VERSION "0.0"

NS_ :

BS_:

BU_: HUB REARSTEER DIFF_F FUEL SENSORV2 POWERTRAIN GPS DIFF_R

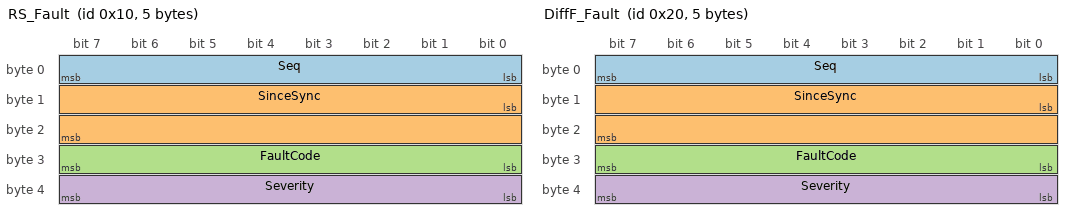
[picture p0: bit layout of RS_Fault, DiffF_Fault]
BO_ 16 RS_Fault: 5 REARSTEER
 SG_ Seq : 0|8@1+ (1,0) [0|255] "" HUB
 SG_ SinceSync : 8|16@1+ (1,0) [0|65534] "us" HUB
 SG_ FaultCode : 24|8@1+ (1,0) [0|254] "" HUB
 SG_ Severity : 32|8@1+ (1,0) [0|254] "" HUB

BO_ 32 DiffF_Fault: 5 DIFF_F
 SG_ Seq : 0|8@1+ (1,0) [0|255] "" HUB
 SG_ SinceSync : 8|16@1+ (1,0) [0|65534] "us" HUB
 SG_ FaultCode : 24|8@1+ (1,0) [0|254] "" HUB
 SG_ Severity : 32|8@1+ (1,0) [0|254] "" HUB

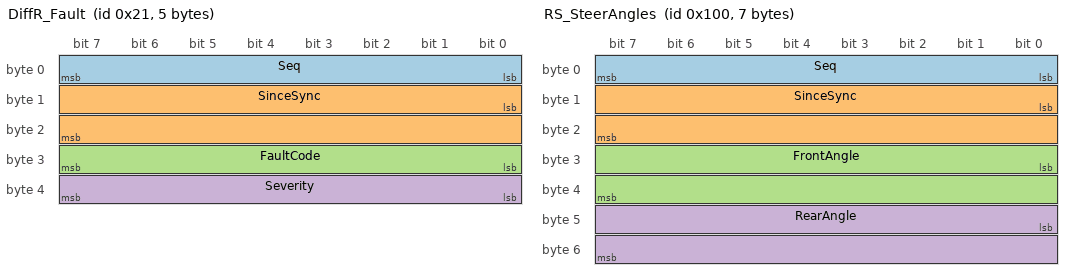
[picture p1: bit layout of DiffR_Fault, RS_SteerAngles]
BO_ 33 DiffR_Fault: 5 DIFF_R
 SG_ Seq : 0|8@1+ (1,0) [0|255] "" HUB
 SG_ SinceSync : 8|16@1+ (1,0) [0|65534] "us" HUB
 SG_ FaultCode : 24|8@1+ (1,0) [0|254] "" HUB
 SG_ Severity : 32|8@1+ (1,0) [0|254] "" HUB

BO_ 128 SYNC: 1 HUB
 SG_ SyncCounter : 0|8@1+ (1,0) [0|255] "" REARSTEER,DIFF_F,FUEL,SENSORV2,POWERTRAIN,GPS,DIFF_R

BO_ 144 GPS_Time: 4 GPS
 SG_ UtcTimeOfDay : 0|32@1+ (1,0) [0|4294967294] "ms" HUB

BO_ 256 RS_SteerAngles: 7 REARSTEER
 SG_ Seq : 0|8@1+ (1,0) [0|255] "" HUB
 SG_ SinceSync : 8|16@1+ (1,0) [0|65534] "us" HUB
 SG_ FrontAngle : 24|16@1- (0.01,0) [-327.68|327.66] "deg" HUB
 SG_ RearAngle : 40|16@1- (0.01,0) [-327.68|327.66] "deg" HUB

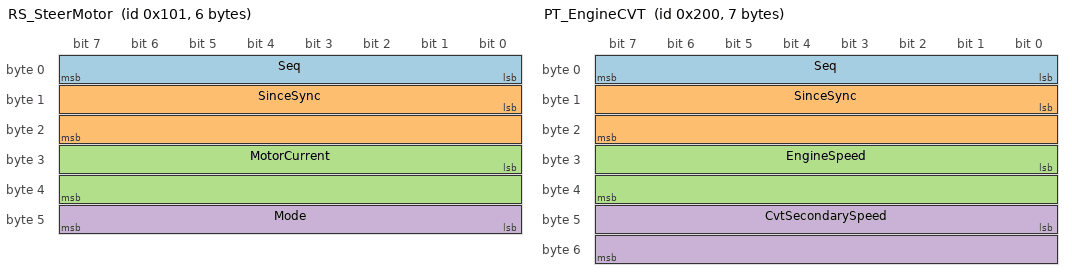
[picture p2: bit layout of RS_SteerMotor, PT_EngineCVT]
BO_ 257 RS_SteerMotor: 6 REARSTEER
 SG_ Seq : 0|8@1+ (1,0) [0|255] "" HUB
 SG_ SinceSync : 8|16@1+ (1,0) [0|65534] "us" HUB
 SG_ MotorCurrent : 24|16@1- (0.01,0) [-327.68|327.66] "A" HUB
 SG_ Mode : 40|8@1+ (1,0) [0|254] "" HUB

BO_ 512 PT_EngineCVT: 7 POWERTRAIN
 SG_ Seq : 0|8@1+ (1,0) [0|255] "" HUB
 SG_ SinceSync : 8|16@1+ (1,0) [0|65534] "us" HUB
 SG_ EngineSpeed : 24|16@1+ (1,0) [0|65534] "rpm" HUB
 SG_ CvtSecondarySpeed : 40|16@1+ (1,0) [0|65534] "rpm" HUB

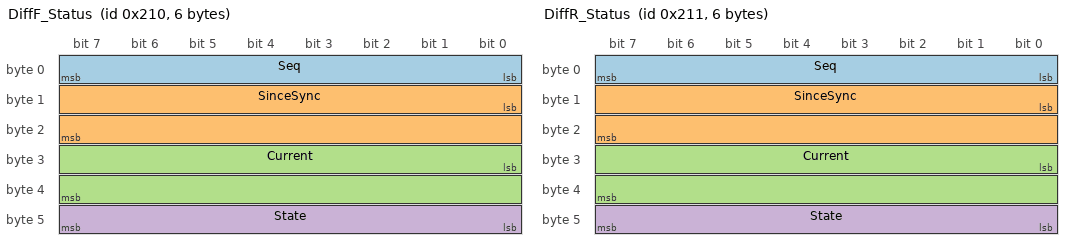
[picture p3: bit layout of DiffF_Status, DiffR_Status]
BO_ 528 DiffF_Status: 6 DIFF_F
 SG_ Seq : 0|8@1+ (1,0) [0|255] "" HUB
 SG_ SinceSync : 8|16@1+ (1,0) [0|65534] "us" HUB
 SG_ Current : 24|16@1- (0.01,0) [-327.68|327.66] "A" HUB
 SG_ State : 40|8@1+ (1,0) [0|254] "" HUB

BO_ 529 DiffR_Status: 6 DIFF_R
 SG_ Seq : 0|8@1+ (1,0) [0|255] "" HUB
 SG_ SinceSync : 8|16@1+ (1,0) [0|65534] "us" HUB
 SG_ Current : 24|16@1- (0.01,0) [-327.68|327.66] "A" HUB
 SG_ State : 40|8@1+ (1,0) [0|254] "" HUB

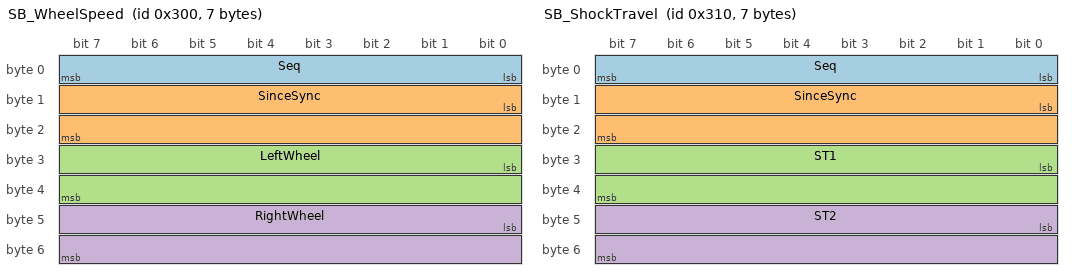
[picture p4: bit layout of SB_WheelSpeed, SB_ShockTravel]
BO_ 768 SB_WheelSpeed: 7 SENSORV2
 SG_ Seq : 0|8@1+ (1,0) [0|255] "" HUB
 SG_ SinceSync : 8|16@1+ (1,0) [0|65534] "us" HUB
 SG_ LeftWheel : 24|16@1+ (0.1,0) [0|6553.4] "rpm" HUB
 SG_ RightWheel : 40|16@1+ (0.1,0) [0|6553.4] "rpm" HUB

BO_ 784 SB_ShockTravel: 7 SENSORV2
 SG_ Seq : 0|8@1+ (1,0) [0|255] "" HUB
 SG_ SinceSync : 8|16@1+ (1,0) [0|65534] "us" HUB
 SG_ ST1 : 24|16@1+ (0.01,0) [0|655.34] "mm" HUB
 SG_ ST2 : 40|16@1+ (0.01,0) [0|655.34] "mm" HUB

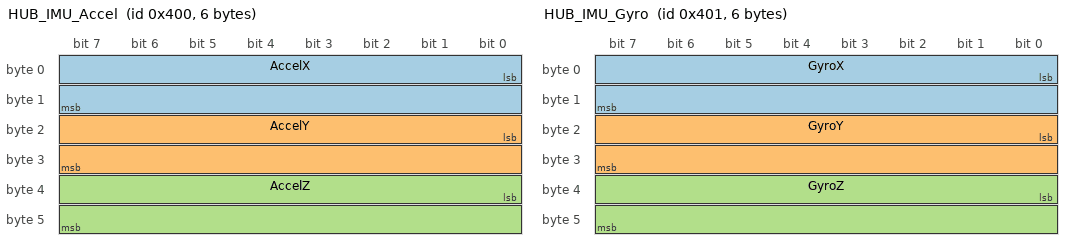
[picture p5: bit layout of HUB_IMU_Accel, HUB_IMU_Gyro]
BO_ 1024 HUB_IMU_Accel: 6 HUB
 SG_ AccelX : 0|16@1- (0.001,0) [-32.768|32.766] "g" Vector__XXX
 SG_ AccelY : 16|16@1- (0.001,0) [-32.768|32.766] "g" Vector__XXX
 SG_ AccelZ : 32|16@1- (0.001,0) [-32.768|32.766] "g" Vector__XXX

BO_ 1025 HUB_IMU_Gyro: 6 HUB
 SG_ GyroX : 0|16@1- (0.1,0) [-3276.8|3276.6] "deg/s" Vector__XXX
 SG_ GyroY : 16|16@1- (0.1,0) [-3276.8|3276.6] "deg/s" Vector__XXX
 SG_ GyroZ : 32|16@1- (0.1,0) [-3276.8|3276.6] "deg/s" Vector__XXX

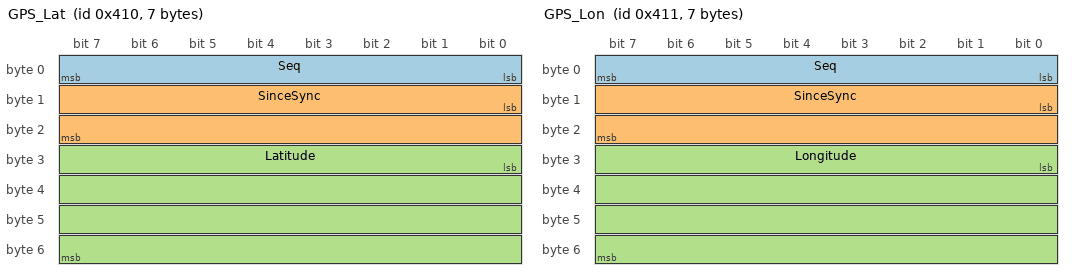
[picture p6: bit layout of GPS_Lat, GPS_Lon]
BO_ 1040 GPS_Lat: 7 GPS
 SG_ Seq : 0|8@1+ (1,0) [0|255] "" HUB
 SG_ SinceSync : 8|16@1+ (1,0) [0|65534] "us" HUB
 SG_ Latitude : 24|32@1- (1e-07,0) [-214.7483648|214.7483646] "deg" HUB

BO_ 1041 GPS_Lon: 7 GPS
 SG_ Seq : 0|8@1+ (1,0) [0|255] "" HUB
 SG_ SinceSync : 8|16@1+ (1,0) [0|65534] "us" HUB
 SG_ Longitude : 24|32@1- (1e-07,0) [-214.7483648|214.7483646] "deg" HUB

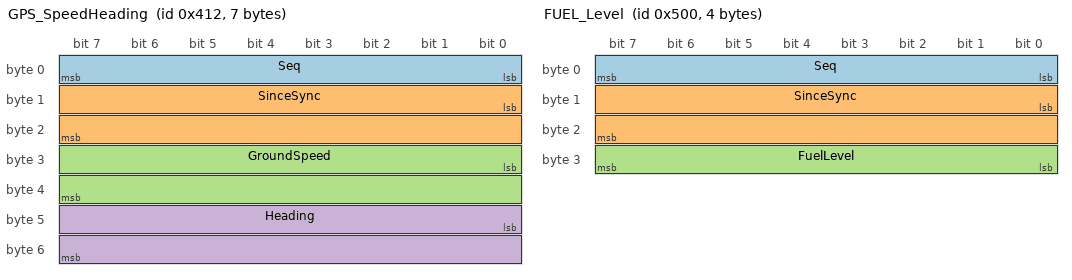
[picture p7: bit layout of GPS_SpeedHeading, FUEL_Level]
BO_ 1042 GPS_SpeedHeading: 7 GPS
 SG_ Seq : 0|8@1+ (1,0) [0|255] "" HUB
 SG_ SinceSync : 8|16@1+ (1,0) [0|65534] "us" HUB
 SG_ GroundSpeed : 24|16@1+ (0.01,0) [0|655.34] "m/s" HUB
 SG_ Heading : 40|16@1+ (0.01,0) [0|655.34] "deg" HUB

BO_ 1280 FUEL_Level: 4 FUEL
 SG_ Seq : 0|8@1+ (1,0) [0|255] "" HUB
 SG_ SinceSync : 8|16@1+ (1,0) [0|65534] "us" HUB
 SG_ FuelLevel : 24|8@1+ (0.5,0) [0|127] "%" HUB

BO_ 1296 HUB_Battery: 2 HUB
 SG_ BatteryVoltage : 0|16@1+ (0.01,0) [0|655.34] "V" Vector__XXX

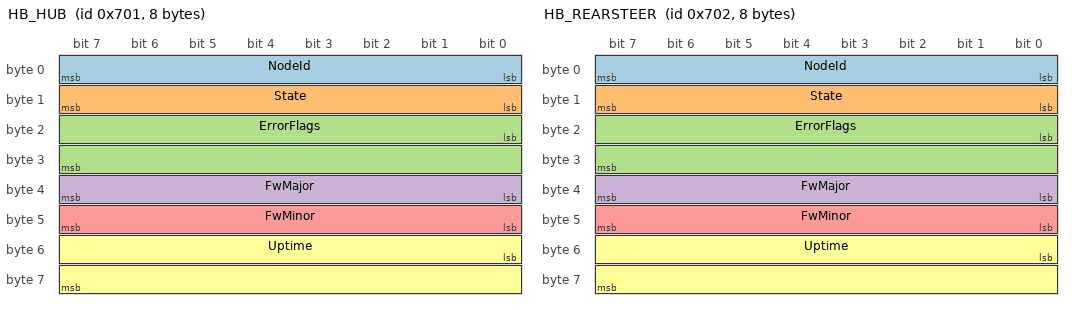
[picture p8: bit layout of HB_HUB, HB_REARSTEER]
BO_ 1793 HB_HUB: 8 HUB
 SG_ NodeId : 0|8@1+ (1,0) [0|255] "" Vector__XXX
 SG_ State : 8|8@1+ (1,0) [0|254] "" Vector__XXX
 SG_ ErrorFlags : 16|16@1+ (1,0) [0|65534] "" Vector__XXX
 SG_ FwMajor : 32|8@1+ (1,0) [0|254] "" Vector__XXX
 SG_ FwMinor : 40|8@1+ (1,0) [0|254] "" Vector__XXX
 SG_ Uptime : 48|16@1+ (1,0) [0|65534] "s" Vector__XXX

BO_ 1794 HB_REARSTEER: 8 REARSTEER
 SG_ NodeId : 0|8@1+ (1,0) [0|255] "" HUB
 SG_ State : 8|8@1+ (1,0) [0|254] "" HUB
 SG_ ErrorFlags : 16|16@1+ (1,0) [0|65534] "" HUB
 SG_ FwMajor : 32|8@1+ (1,0) [0|254] "" HUB
 SG_ FwMinor : 40|8@1+ (1,0) [0|254] "" HUB
 SG_ Uptime : 48|16@1+ (1,0) [0|65534] "s" HUB

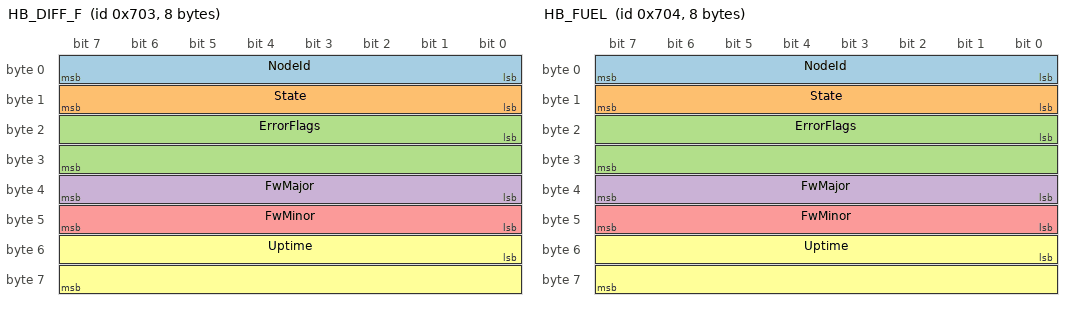
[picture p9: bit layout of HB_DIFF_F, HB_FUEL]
BO_ 1795 HB_DIFF_F: 8 DIFF_F
 SG_ NodeId : 0|8@1+ (1,0) [0|255] "" HUB
 SG_ State : 8|8@1+ (1,0) [0|254] "" HUB
 SG_ ErrorFlags : 16|16@1+ (1,0) [0|65534] "" HUB
 SG_ FwMajor : 32|8@1+ (1,0) [0|254] "" HUB
 SG_ FwMinor : 40|8@1+ (1,0) [0|254] "" HUB
 SG_ Uptime : 48|16@1+ (1,0) [0|65534] "s" HUB

BO_ 1796 HB_FUEL: 8 FUEL
 SG_ NodeId : 0|8@1+ (1,0) [0|255] "" HUB
 SG_ State : 8|8@1+ (1,0) [0|254] "" HUB
 SG_ ErrorFlags : 16|16@1+ (1,0) [0|65534] "" HUB
 SG_ FwMajor : 32|8@1+ (1,0) [0|254] "" HUB
 SG_ FwMinor : 40|8@1+ (1,0) [0|254] "" HUB
 SG_ Uptime : 48|16@1+ (1,0) [0|65534] "s" HUB

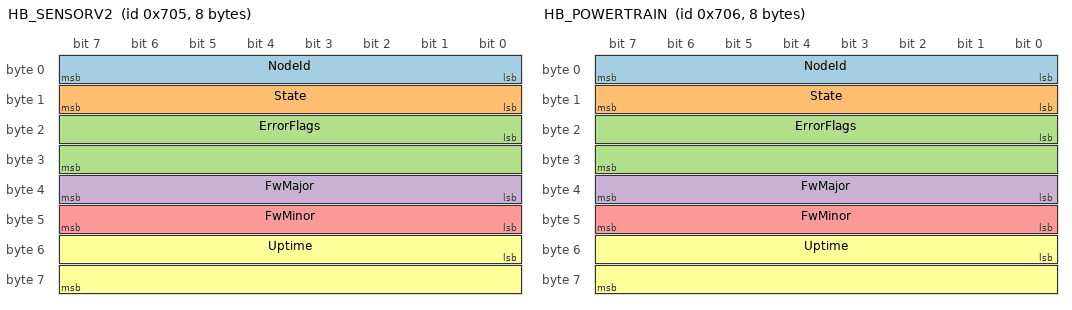
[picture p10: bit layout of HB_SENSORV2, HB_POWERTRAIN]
BO_ 1797 HB_SENSORV2: 8 SENSORV2
 SG_ NodeId : 0|8@1+ (1,0) [0|255] "" HUB
 SG_ State : 8|8@1+ (1,0) [0|254] "" HUB
 SG_ ErrorFlags : 16|16@1+ (1,0) [0|65534] "" HUB
 SG_ FwMajor : 32|8@1+ (1,0) [0|254] "" HUB
 SG_ FwMinor : 40|8@1+ (1,0) [0|254] "" HUB
 SG_ Uptime : 48|16@1+ (1,0) [0|65534] "s" HUB

BO_ 1798 HB_POWERTRAIN: 8 POWERTRAIN
 SG_ NodeId : 0|8@1+ (1,0) [0|255] "" HUB
 SG_ State : 8|8@1+ (1,0) [0|254] "" HUB
 SG_ ErrorFlags : 16|16@1+ (1,0) [0|65534] "" HUB
 SG_ FwMajor : 32|8@1+ (1,0) [0|254] "" HUB
 SG_ FwMinor : 40|8@1+ (1,0) [0|254] "" HUB
 SG_ Uptime : 48|16@1+ (1,0) [0|65534] "s" HUB

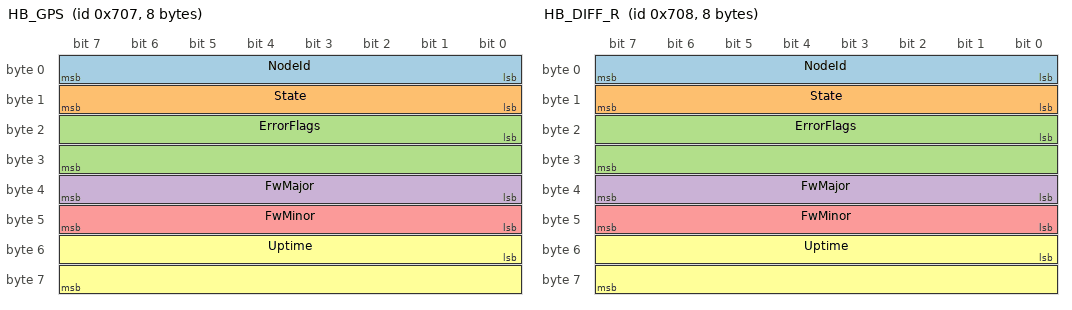
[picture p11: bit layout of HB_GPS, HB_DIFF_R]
BO_ 1799 HB_GPS: 8 GPS
 SG_ NodeId : 0|8@1+ (1,0) [0|255] "" HUB
 SG_ State : 8|8@1+ (1,0) [0|254] "" HUB
 SG_ ErrorFlags : 16|16@1+ (1,0) [0|65534] "" HUB
 SG_ FwMajor : 32|8@1+ (1,0) [0|254] "" HUB
 SG_ FwMinor : 40|8@1+ (1,0) [0|254] "" HUB
 SG_ Uptime : 48|16@1+ (1,0) [0|65534] "s" HUB

BO_ 1800 HB_DIFF_R: 8 DIFF_R
 SG_ NodeId : 0|8@1+ (1,0) [0|255] "" HUB
 SG_ State : 8|8@1+ (1,0) [0|254] "" HUB
 SG_ ErrorFlags : 16|16@1+ (1,0) [0|65534] "" HUB
 SG_ FwMajor : 32|8@1+ (1,0) [0|254] "" HUB
 SG_ FwMinor : 40|8@1+ (1,0) [0|254] "" HUB
 SG_ Uptime : 48|16@1+ (1,0) [0|65534] "s" HUB

CM_ "Baja DAQ CAN spec v0 (frozen Oct 19 2026). CAN 2.0A, 1 Mbit/s, little-endian. All-ones raw value (0xFF, 0xFFFF, 0x7FFF signed) = not available. Owner: Toph Jones.";
CM_ SG_ 16 Seq "Sequence counter, +1 per message on this ID, wraps 255->0";
CM_ SG_ 16 SinceSync "us since last SYNC (0x080); 0xFFFF = no SYNC yet";
CM_ BO_ 16 "Sent on change, then 10 Hz while active";
CM_ SG_ 32 Seq "Sequence counter, +1 per message on this ID, wraps 255->0";
CM_ SG_ 32 SinceSync "us since last SYNC (0x080); 0xFFFF = no SYNC yet";
CM_ SG_ 32 FaultCode "Codes defined by diff team";
CM_ BO_ 32 "Sent on change, then 10 Hz while active";
CM_ SG_ 33 Seq "Sequence counter, +1 per message on this ID, wraps 255->0";
CM_ SG_ 33 SinceSync "us since last SYNC (0x080); 0xFFFF = no SYNC yet";
CM_ SG_ 33 FaultCode "Codes defined by diff team";
CM_ BO_ 33 "Sent on change, then 10 Hz while active";
CM_ BO_ 128 "No header. Nodes reset their us counter on receipt";
CM_ BO_ 144 "No header. Sent on PPS";
CM_ SG_ 256 Seq "Sequence counter, +1 per message on this ID, wraps 255->0";
CM_ SG_ 256 SinceSync "us since last SYNC (0x080); 0xFFFF = no SYNC yet";
CM_ SG_ 257 Seq "Sequence counter, +1 per message on this ID, wraps 255->0";
CM_ SG_ 257 SinceSync "us since last SYNC (0x080); 0xFFFF = no SYNC yet";
CM_ SG_ 512 Seq "Sequence counter, +1 per message on this ID, wraps 255->0";
CM_ SG_ 512 SinceSync "us since last SYNC (0x080); 0xFFFF = no SYNC yet";
CM_ SG_ 528 Seq "Sequence counter, +1 per message on this ID, wraps 255->0";
CM_ SG_ 528 SinceSync "us since last SYNC (0x080); 0xFFFF = no SYNC yet";
CM_ SG_ 528 State "Values defined by diff team";
CM_ SG_ 529 Seq "Sequence counter, +1 per message on this ID, wraps 255->0";
CM_ SG_ 529 SinceSync "us since last SYNC (0x080); 0xFFFF = no SYNC yet";
CM_ SG_ 529 State "Values defined by diff team";
CM_ SG_ 768 Seq "Sequence counter, +1 per message on this ID, wraps 255->0";
CM_ SG_ 768 SinceSync "us since last SYNC (0x080); 0xFFFF = no SYNC yet";
CM_ SG_ 784 Seq "Sequence counter, +1 per message on this ID, wraps 255->0";
CM_ SG_ 784 SinceSync "us since last SYNC (0x080); 0xFFFF = no SYNC yet";
CM_ BO_ 784 "Assumes ST1/ST2 are shock travel; confirm with shock team";
CM_ BO_ 1024 "Hub-internal: logged with this ID, never transmitted. No header";
CM_ BO_ 1025 "Hub-internal: logged with this ID, never transmitted. No header";
CM_ SG_ 1040 Seq "Sequence counter, +1 per message on this ID, wraps 255->0";
CM_ SG_ 1040 SinceSync "us since last SYNC (0x080); 0xFFFF = no SYNC yet";
CM_ SG_ 1041 Seq "Sequence counter, +1 per message on this ID, wraps 255->0";
CM_ SG_ 1041 SinceSync "us since last SYNC (0x080); 0xFFFF = no SYNC yet";
CM_ SG_ 1042 Seq "Sequence counter, +1 per message on this ID, wraps 255->0";
CM_ SG_ 1042 SinceSync "us since last SYNC (0x080); 0xFFFF = no SYNC yet";
CM_ SG_ 1280 Seq "Sequence counter, +1 per message on this ID, wraps 255->0";
CM_ SG_ 1280 SinceSync "us since last SYNC (0x080); 0xFFFF = no SYNC yet";
CM_ BO_ 1296 "Hub-internal: logged with this ID, never transmitted. No header";
CM_ SG_ 1793 ErrorFlags "Bits 0-7 node library: 0 no SYNC seen, 1 CAN error-passive since last HB, 2 TX queue overflow, 3 brownout/watchdog reset. Bits 8-15 node-specific";
CM_ SG_ 1793 Uptime "Seconds since power-up, wraps";
CM_ BO_ 1793 "Heartbeat, DAQ hub. No header";
CM_ SG_ 1794 ErrorFlags "Bits 0-7 node library: 0 no SYNC seen, 1 CAN error-passive since last HB, 2 TX queue overflow, 3 brownout/watchdog reset. Bits 8-15 node-specific";
CM_ SG_ 1794 Uptime "Seconds since power-up, wraps";
CM_ BO_ 1794 "Heartbeat, Rear-steer controller. No header";
CM_ SG_ 1795 ErrorFlags "Bits 0-7 node library: 0 no SYNC seen, 1 CAN error-passive since last HB, 2 TX queue overflow, 3 brownout/watchdog reset. Bits 8-15 node-specific";
CM_ SG_ 1795 Uptime "Seconds since power-up, wraps";
CM_ BO_ 1795 "Heartbeat, Front diff controller. No header";
CM_ SG_ 1796 ErrorFlags "Bits 0-7 node library: 0 no SYNC seen, 1 CAN error-passive since last HB, 2 TX queue overflow, 3 brownout/watchdog reset. Bits 8-15 node-specific";
CM_ SG_ 1796 Uptime "Seconds since power-up, wraps";
CM_ BO_ 1796 "Heartbeat, Fuel gauge (PIC). No header";
CM_ SG_ 1797 ErrorFlags "Bits 0-7 node library: 0 no SYNC seen, 1 CAN error-passive since last HB, 2 TX queue overflow, 3 brownout/watchdog reset. Bits 8-15 node-specific";
CM_ SG_ 1797 Uptime "Seconds since power-up, wraps";
CM_ BO_ 1797 "Heartbeat, SensorBoardV2: wheel speed, shock travel. No header";
CM_ SG_ 1798 ErrorFlags "Bits 0-7 node library: 0 no SYNC seen, 1 CAN error-passive since last HB, 2 TX queue overflow, 3 brownout/watchdog reset. Bits 8-15 node-specific";
CM_ SG_ 1798 Uptime "Seconds since power-up, wraps";
CM_ BO_ 1798 "Heartbeat, Engine and CVT speed node (unplanned, ID reserved). No header";
CM_ SG_ 1799 ErrorFlags "Bits 0-7 node library: 0 no SYNC seen, 1 CAN error-passive since last HB, 2 TX queue overflow, 3 brownout/watchdog reset. Bits 8-15 node-specific";
CM_ SG_ 1799 Uptime "Seconds since power-up, wraps";
CM_ BO_ 1799 "Heartbeat, GPS node (DAQ, if built). No header";
CM_ SG_ 1800 ErrorFlags "Bits 0-7 node library: 0 no SYNC seen, 1 CAN error-passive since last HB, 2 TX queue overflow, 3 brownout/watchdog reset. Bits 8-15 node-specific";
CM_ SG_ 1800 Uptime "Seconds since power-up, wraps";
CM_ BO_ 1800 "Heartbeat, Rear diff controller. No header";
CM_ BU_ HUB "Node ID 0x01: DAQ hub";
CM_ BU_ REARSTEER "Node ID 0x02: Rear-steer controller";
CM_ BU_ DIFF_F "Node ID 0x03: Front diff controller";
CM_ BU_ FUEL "Node ID 0x04: Fuel gauge (PIC)";
CM_ BU_ SENSORV2 "Node ID 0x05: SensorBoardV2: wheel speed, shock travel";
CM_ BU_ POWERTRAIN "Node ID 0x06: Engine and CVT speed node (unplanned, ID reserved)";
CM_ BU_ GPS "Node ID 0x07: GPS node (DAQ, if built)";
CM_ BU_ DIFF_R "Node ID 0x08: Rear diff controller";

BA_DEF_ BO_ "GenMsgCycleTime" INT 0 65535;
BA_DEF_ BO_ "HubInternal" INT 0 1;
BA_DEF_DEF_ "GenMsgCycleTime" 0;
BA_DEF_DEF_ "HubInternal" 0;
BA_ "GenMsgCycleTime" BO_ 128 50;
BA_ "GenMsgCycleTime" BO_ 144 1000;
BA_ "GenMsgCycleTime" BO_ 256 10;
BA_ "GenMsgCycleTime" BO_ 257 10;
BA_ "GenMsgCycleTime" BO_ 512 10;
BA_ "GenMsgCycleTime" BO_ 528 20;
BA_ "GenMsgCycleTime" BO_ 529 20;
BA_ "GenMsgCycleTime" BO_ 768 10;
BA_ "GenMsgCycleTime" BO_ 784 2;
BA_ "GenMsgCycleTime" BO_ 1024 2;
BA_ "HubInternal" BO_ 1024 1;
BA_ "GenMsgCycleTime" BO_ 1025 2;
BA_ "HubInternal" BO_ 1025 1;
BA_ "GenMsgCycleTime" BO_ 1040 100;
BA_ "GenMsgCycleTime" BO_ 1041 100;
BA_ "GenMsgCycleTime" BO_ 1042 100;
BA_ "GenMsgCycleTime" BO_ 1280 1000;
BA_ "GenMsgCycleTime" BO_ 1296 100;
BA_ "HubInternal" BO_ 1296 1;
BA_ "GenMsgCycleTime" BO_ 1793 1000;
BA_ "GenMsgCycleTime" BO_ 1794 1000;
BA_ "GenMsgCycleTime" BO_ 1795 1000;
BA_ "GenMsgCycleTime" BO_ 1796 1000;
BA_ "GenMsgCycleTime" BO_ 1797 1000;
BA_ "GenMsgCycleTime" BO_ 1798 1000;
BA_ "GenMsgCycleTime" BO_ 1799 1000;
BA_ "GenMsgCycleTime" BO_ 1800 1000;

VAL_ 16 FaultCode 0 "NONE" 1 "OVERCURRENT" 2 "FRONT_POT_FAULT" 3 "REAR_POT_FAULT" 4 "TRACKING_ERROR" 5 "UNDERVOLTAGE" ;
VAL_ 16 Severity 1 "WARNING" 2 "CRITICAL" ;
VAL_ 32 Severity 1 "WARNING" 2 "CRITICAL" ;
VAL_ 33 Severity 1 "WARNING" 2 "CRITICAL" ;
VAL_ 257 Mode 0 "DISABLED" 1 "ACTIVE" 2 "CENTERING" 3 "FAULT_STOP" ;
VAL_ 1793 State 0 "BOOTING" 1 "OK" 2 "WARNING" 3 "FAULT" ;
VAL_ 1794 State 0 "BOOTING" 1 "OK" 2 "WARNING" 3 "FAULT" ;
VAL_ 1795 State 0 "BOOTING" 1 "OK" 2 "WARNING" 3 "FAULT" ;
VAL_ 1796 State 0 "BOOTING" 1 "OK" 2 "WARNING" 3 "FAULT" ;
VAL_ 1797 State 0 "BOOTING" 1 "OK" 2 "WARNING" 3 "FAULT" ;
VAL_ 1798 State 0 "BOOTING" 1 "OK" 2 "WARNING" 3 "FAULT" ;
VAL_ 1799 State 0 "BOOTING" 1 "OK" 2 "WARNING" 3 "FAULT" ;
VAL_ 1800 State 0 "BOOTING" 1 "OK" 2 "WARNING" 3 "FAULT" ;
